# DA14683 register map
Vendor: Dialog; Series: DA14683; File version: 1.2
CPU: CM0 r1p0, little endian, MPU, FPU, 3 interrupt priority bits
Registers are 16-bit, read-write, reset 0x0 unless marked. A register's access mark holds for its fields unless they carry their own. Offsets are from the block's base; [hi:lo] are bit positions; {n}, {i} and the like mark numbered series; 'fields as' and 'values as' point back to an identical list.

## GPIO — GPIO registers
Base 0x50003000
0x00 P0_DATA_REG reset 0x20 — P0 Data input / output Register
  [7:0] P0_DATA — Set P0 output register when written; Returns the value of P0 port when read
0x02 P1_DATA_REG reset 0x60 — P1 Data input / output Register
  [7:0] P1_DATA — Set P1 output register when written; Returns the value of P1 port when read
0x04 P2_DATA_REG — P2 Data input / output Register
  [4:0] P2_DATA — Set P2 output register when written; Returns the value of P2 port when read
0x06 P3_DATA_REG — P3 Data input / output Register
  [7:0] P3_DATA — Set P3 output register when written; Returns the value of P3 port when read
0x08 P4_DATA_REG — P4 Data input / output Register
  [7:0] P4_DATA — Set P4 output register when written; Returns the value of P4 port when read
0x0A P0_SET_DATA_REG — P0 Set port pins Register
  [7:0] P0_SET wo — Writing a 1 to P0[y] sets P0[y] to 1. Writing 0 is discarded; Reading returns 0
0x0C P1_SET_DATA_REG — P1 Set port pins Register
  [7:0] P1_SET wo — Writing a 1 to P1[y] sets P1[y] to 1. Writing 0 is discarded; Reading returns 0
0x0E P2_SET_DATA_REG — P2 Set port pins Register
  [4:0] P2_SET wo — Writing a 1 to P2[y] sets P2[y] to 1. Writing 0 is discarded; Reading returns 0
0x10 P3_SET_DATA_REG — P3 Set port pins Register
  [7:0] P3_SET wo — Writing a 1 to P3[y] sets P3[y] to 1. Writing 0 is discarded; Reading returns 0
0x12 P4_SET_DATA_REG — P4 Set port pins Register
  [7:0] P4_SET wo — Writing a 1 to P4[y] sets P4[y] to 1. Writing 0 is discarded; Reading returns 0
0x14 P0_RESET_DATA_REG — P0 Reset port pins Register
  [7:0] P0_RESET wo — Writing a 1 to P0[y] sets P0[y] to 0. Writing 0 is discarded; Reading returns 0
0x16 P1_RESET_DATA_REG — P1 Reset port pins Register
  [7:0] P1_RESET wo — Writing a 1 to P1[y] sets P1[y] to 0. Writing 0 is discarded; Reading returns 0
0x18 P2_RESET_DATA_REG — P2 Reset port pins Register
  [4:0] P2_RESET wo — Writing a 1 to P2[y] sets P2[y] to 0. Writing 0 is discarded; Reading returns 0
0x1A P3_RESET_DATA_REG — P3 Reset port pins Register
  [7:0] P3_RESET wo — Writing a 1 to P3[y] sets P3[y] to 0. Writing 0 is discarded; Reading returns 0
0x1C P4_RESET_DATA_REG — P4 Reset port pins Register
  [7:0] P4_RESET wo — Writing a 1 to P4[y] sets P4[y] to 0. Writing 0 is discarded; Reading returns 0
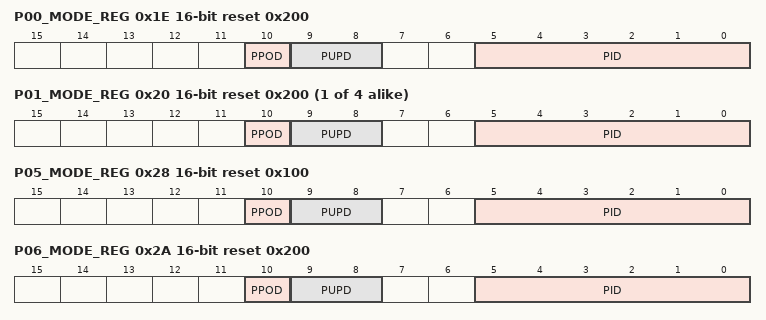
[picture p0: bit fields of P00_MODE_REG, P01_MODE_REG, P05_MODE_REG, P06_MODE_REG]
0x1E P00_MODE_REG reset 0x200 — P00 Mode Register
  [10] PPOD — 0: Push pull 1: Open drain
  [9:8] PUPD — 00 = Input, no resistors selected 01 = Input, pull-up selected 10 = Input, pull-down selected 11 = Output, no resistors selected In ADC mode, these bits are don't care
  [5:0] PID — Function of port 0: GPIO, PUPD see above 1: UART_RX 2: UART_TX 3: UART_IRDA_RX 4: UART_IRDA_TX 5: UART2_RX 6: UART2_TX 7: UART2_IRDA_RX 8: UART2_IRDA_TX 9: UART2_CTSN 10: UART2_RTSN 11: SPI_DI 12: SPI_DO 13: SPI_CLK14: SPI_EN 15: SPI2_DI 16: SPI2_DO 17: SPI2_CLK 18: SPI2_EN 19: I2C_SCL 20: I2C_SDA 21: I2C2_SCL 22: I2C2_SDA 23: PWM0 24: PWM1 25: PWM2 26: PWM3 27: PWM4 28: BLE_DIAG (ble_diag_0: pins P2_0 and P3_0, ble_diag_1: pins P2_1 and P3_1, ble_diag_2: pins P2_2 and P3_2, ble_diag_3: pins P1_0 and P3_3, ble_diag_4: pins P1_1 and P3_4, ble_diag_5: pins P1_2 and P3_5, ble_diag_6: pins P1_3 and P3_6, ble_diag_7: pins P2_3 and P3_7) 29: FTDF_DIAG (ftdf_diag_0: pins P1_4 and P4_0, ftdf_diag_1: pins P1_5 and P4_1, ftdf_diag_2: pins P1_6 and P4_2, ftdf_diag_3: pins P1_7 and P4_3, ftdf_diag_4: pins P0_6 and P4_4, ftdf_diag_5: pins P0_7 and P4_5, ftdf_diag_6: pins P1_3 and P4_6, ftdf_diag_7: pins P2_3 and P4_7) 30: PCM_DI 31: PCM_DO 32: PCM_FSC 33: PCM_CLK 34: PDM_DI 35: PDM_DO 36: PDM_CLK 37: USB_SOF 38: ADC (only for P0[7:6], P1[5:2,0] and P2[4]) 38: USB (only for P2[2] and P1[1]) 38: XTAL32 (only for P2[1:0]) 39: QD_CHA_X 40: QD_CHB_X 41: QD_CHA_Y 42: QD_CHB_Y 43: QD_CHA_Z 44: QD_CHB_Z 45: IR_OUT 46: BREATH 47: KB_ROW 48: COEX_EXT_ACT0 49: COEX_EXT_ACT1 50: COEX_SMART_ACT 51: COEX_SMART_PRI 52: CLOCK 53: ONESHOT 54: PWM5 55: PORT0_DCF 56: PORT1_DCF 57: PORT2_DCF 58: PORT3_DCF 59: PORT4_DCF 60: RF_ANT_TRIM[0] 61: RF_ANT_TRIM[1] 62: RF_ANT_TRIM[2] 63: Reserved
{0x1E+2i} P{i:02}_MODE_REG reset 0x200 (i=1..4) — P{i:02} Mode Register
  [10] PPOD — 0: Push pull 1: Open drain
  [9:8] PUPD — 00 = Input, no resistors selected 01 = Input, pull-up selected 10 = Input, pull-down selected 11 = Output, no resistors selected In ADC mode, these bits are don't care
  [5:0] PID — See P00_MODE_REG[PID]
0x28 P05_MODE_REG reset 0x100 — P05 Mode Register
  fields as P01_MODE_REG
0x2A P06_MODE_REG reset 0x200 — P06 Mode Register
  fields as P01_MODE_REG
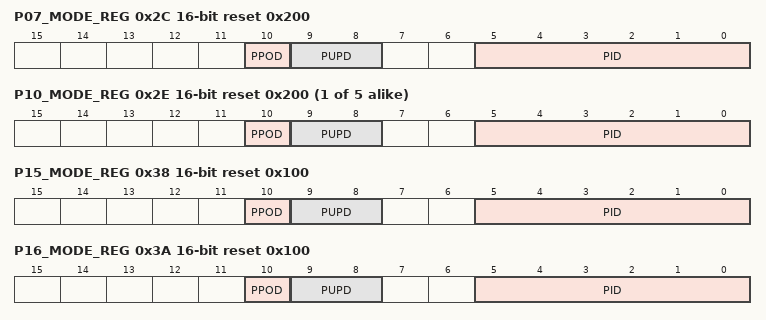
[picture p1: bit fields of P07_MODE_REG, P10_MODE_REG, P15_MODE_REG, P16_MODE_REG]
0x2C P07_MODE_REG reset 0x200 — P07 Mode Register
  fields as P01_MODE_REG
{0x1A+2i} P{i}_MODE_REG reset 0x200 (i=10..14) — P{i} Mode Register
  fields as P01_MODE_REG
0x38 P15_MODE_REG reset 0x100 — P15 Mode Register
  fields as P01_MODE_REG
0x3A P16_MODE_REG reset 0x100 — P24 Mode Register
  fields as P01_MODE_REG
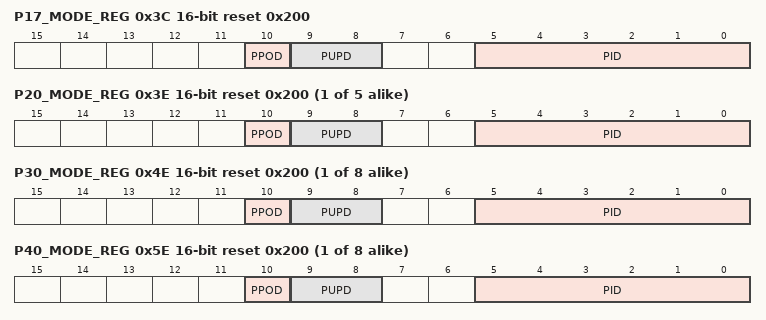
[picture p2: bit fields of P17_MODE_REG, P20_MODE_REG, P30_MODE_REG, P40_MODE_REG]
0x3C P17_MODE_REG reset 0x200 — P25 Mode Register
  fields as P01_MODE_REG
{0x16+2i} P{i}_MODE_REG reset 0x200 (i=20..24) — P{i} Mode Register
  fields as P01_MODE_REG
{0x12+2i} P{i}_MODE_REG reset 0x200 (i=30..37) — P{i} Mode Register
  fields as P01_MODE_REG
{0xE+2i} P{i}_MODE_REG reset 0x200 (i=40..47) — P{i} Mode Register
  fields as P01_MODE_REG
0xC0 P0_PADPWR_CTRL_REG — P0 Output Power Control Register
  [7:6] P0_OUT_CTRL — 1 = P0_x port output is powered by VDD1V8P rail 0 = P0_x port output is powered by V33 rail bit 6 controls the power supply of P0[6], bit 7 controls the power supply of P0[7]
0xC2 P1_PADPWR_CTRL_REG — P1 Output Power Control Register
  [7:0] P1_OUT_CTRL — 1 = P1_x port output is powered by VDD1V8P rail 0 = P1_x port output is powered by V33 rail bit x controls the power supply of P1[x]
0xC4 P2_PADPWR_CTRL_REG — P2 Output Power Control Register
  [4:0] P2_OUT_CTRL — 1 = P2_x port output is powered by VDD1V8P rail 0 = P2_x port output is powered by V33 rail bit x controls the power supply of P2[x]
0xC6 P3_PADPWR_CTRL_REG — P3 Output Power Control Register
  [7:0] P3_OUT_CTRL — 1 = P3_x port output is powered by VDD1V8P rail 0 = P3_x port output is powered by V33 rail bit x controls the power supply of P3[x]
0xC8 P4_PADPWR_CTRL_REG — P4 Output Power Control Register
  [7:0] P4_OUT_CTRL — 1 = P4_x port output is powered by VDD1V8P rail 0 = P4_x port output is powered by V33 rail bit x controls the power supply of P4[x]
0xD0 GPIO_CLK_SEL — Select which clock to map on port in PPA
  [2:0] FUNC_CLOCK_SEL — Select which clock to map when PID = FUNC_CLOCK. 0x0: XTAL32K 0x1: RC32K 0x2: RCX 0x3: XTAL16M 0x4: RC16M 0x5: DIVN 0x6: Reserved 0x7: Reserved
